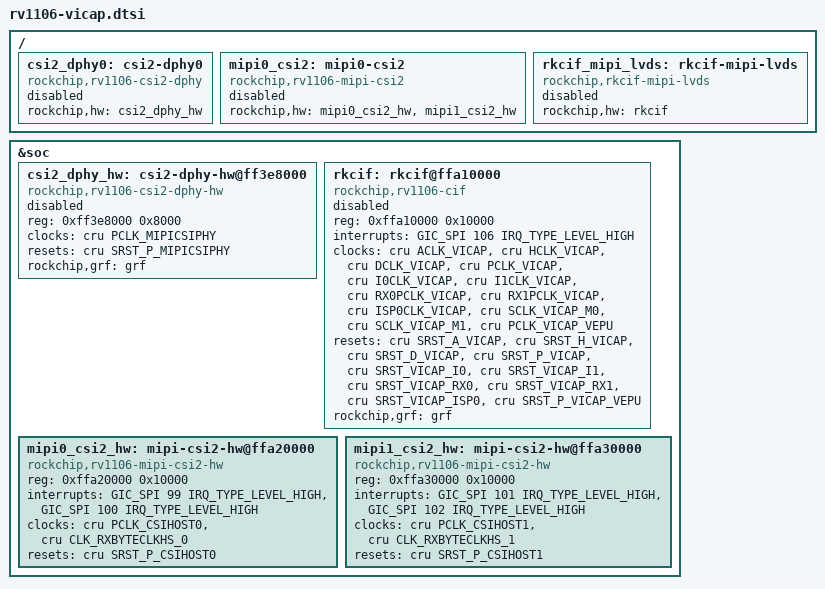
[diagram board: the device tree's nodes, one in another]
// SPDX-License-Identifier: (GPL-2.0+ OR MIT)
/*
 * RV1106 VICAP (CSI2 DPHY + MIPI CSI-2 + RKCIF). Ported from vendor 5.10
 * for Linux 6.18 PicoKVM HDMI capture. ISP / sditf stay disabled.
 */

&soc {
	csi2_dphy_hw: csi2-dphy-hw@ff3e8000 {
		compatible = "rockchip,rv1106-csi2-dphy-hw";
		reg = <0xff3e8000 0x8000>;
		clocks = <&cru PCLK_MIPICSIPHY>;
		clock-names = "pclk";
		resets = <&cru SRST_P_MIPICSIPHY>;
		reset-names = "srst_p_csiphy";
		rockchip,grf = <&grf>;
		status = "disabled";
	};

	rkcif: rkcif@ffa10000 {
		compatible = "rockchip,rv1106-cif";
		reg = <0xffa10000 0x10000>;
		reg-names = "cif_regs";
		interrupts = <GIC_SPI 106 IRQ_TYPE_LEVEL_HIGH>;
		interrupt-names = "cif-intr";
		clocks = <&cru ACLK_VICAP>, <&cru HCLK_VICAP>,
			 <&cru DCLK_VICAP>, <&cru PCLK_VICAP>,
			 <&cru I0CLK_VICAP>, <&cru I1CLK_VICAP>,
			 <&cru RX0PCLK_VICAP>, <&cru RX1PCLK_VICAP>,
			 <&cru ISP0CLK_VICAP>, <&cru SCLK_VICAP_M0>,
			 <&cru SCLK_VICAP_M1>, <&cru PCLK_VICAP_VEPU>;
		clock-names = "aclk_cif", "hclk_cif",
			      "dclk_cif", "pclk_cif",
			      "i0clk_cif", "i1clk_cif",
			      "rx0clk_cif", "rx1clk_cif",
			      "isp0clk_cif", "sclk_m0_cif",
			      "sclk_m1_cif", "pclk_vepu_cif";
		resets = <&cru SRST_A_VICAP>, <&cru SRST_H_VICAP>,
			 <&cru SRST_D_VICAP>, <&cru SRST_P_VICAP>,
			 <&cru SRST_VICAP_I0>, <&cru SRST_VICAP_I1>,
			 <&cru SRST_VICAP_RX0>, <&cru SRST_VICAP_RX1>,
			 <&cru SRST_VICAP_ISP0>, <&cru SRST_P_VICAP_VEPU>;
		reset-names = "rst_cif_a", "rst_cif_h",
			      "rst_cif_d", "rst_cif_p",
			      "rst_cif_i0", "rst_cif_i1",
			      "rst_cif_rx0", "rst_cif_rx1",
			      "rst_cif_isp0", "rst_cif_pclk_vepu";
		rockchip,grf = <&grf>;
		status = "disabled";
	};

	mipi0_csi2_hw: mipi-csi2-hw@ffa20000 {
		compatible = "rockchip,rv1106-mipi-csi2-hw";
		reg = <0xffa20000 0x10000>;
		reg-names = "csihost_regs";
		interrupts = <GIC_SPI 99 IRQ_TYPE_LEVEL_HIGH>,
			     <GIC_SPI 100 IRQ_TYPE_LEVEL_HIGH>;
		interrupt-names = "csi-intr1", "csi-intr2";
		clocks = <&cru PCLK_CSIHOST0>, <&cru CLK_RXBYTECLKHS_0>;
		clock-names = "pclk_csi2host", "clk_rxbyte_hs";
		resets = <&cru SRST_P_CSIHOST0>;
		reset-names = "srst_csihost_p";
		status = "okay";
	};

	mipi1_csi2_hw: mipi-csi2-hw@ffa30000 {
		compatible = "rockchip,rv1106-mipi-csi2-hw";
		reg = <0xffa30000 0x10000>;
		reg-names = "csihost_regs";
		interrupts = <GIC_SPI 101 IRQ_TYPE_LEVEL_HIGH>,
			     <GIC_SPI 102 IRQ_TYPE_LEVEL_HIGH>;
		interrupt-names = "csi-intr1", "csi-intr2";
		clocks = <&cru PCLK_CSIHOST1>, <&cru CLK_RXBYTECLKHS_1>;
		clock-names = "pclk_csi2host", "clk_rxbyte_hs";
		resets = <&cru SRST_P_CSIHOST1>;
		reset-names = "srst_csihost_p";
		status = "okay";
	};
};

/ {
	csi2_dphy0: csi2-dphy0 {
		compatible = "rockchip,rv1106-csi2-dphy";
		rockchip,hw = <&csi2_dphy_hw>;
		status = "disabled";
	};

	mipi0_csi2: mipi0-csi2 {
		compatible = "rockchip,rv1106-mipi-csi2";
		rockchip,hw = <&mipi0_csi2_hw>, <&mipi1_csi2_hw>;
		status = "disabled";
	};

	rkcif_mipi_lvds: rkcif-mipi-lvds {
		compatible = "rockchip,rkcif-mipi-lvds";
		rockchip,hw = <&rkcif>;
		status = "disabled";
	};
};
